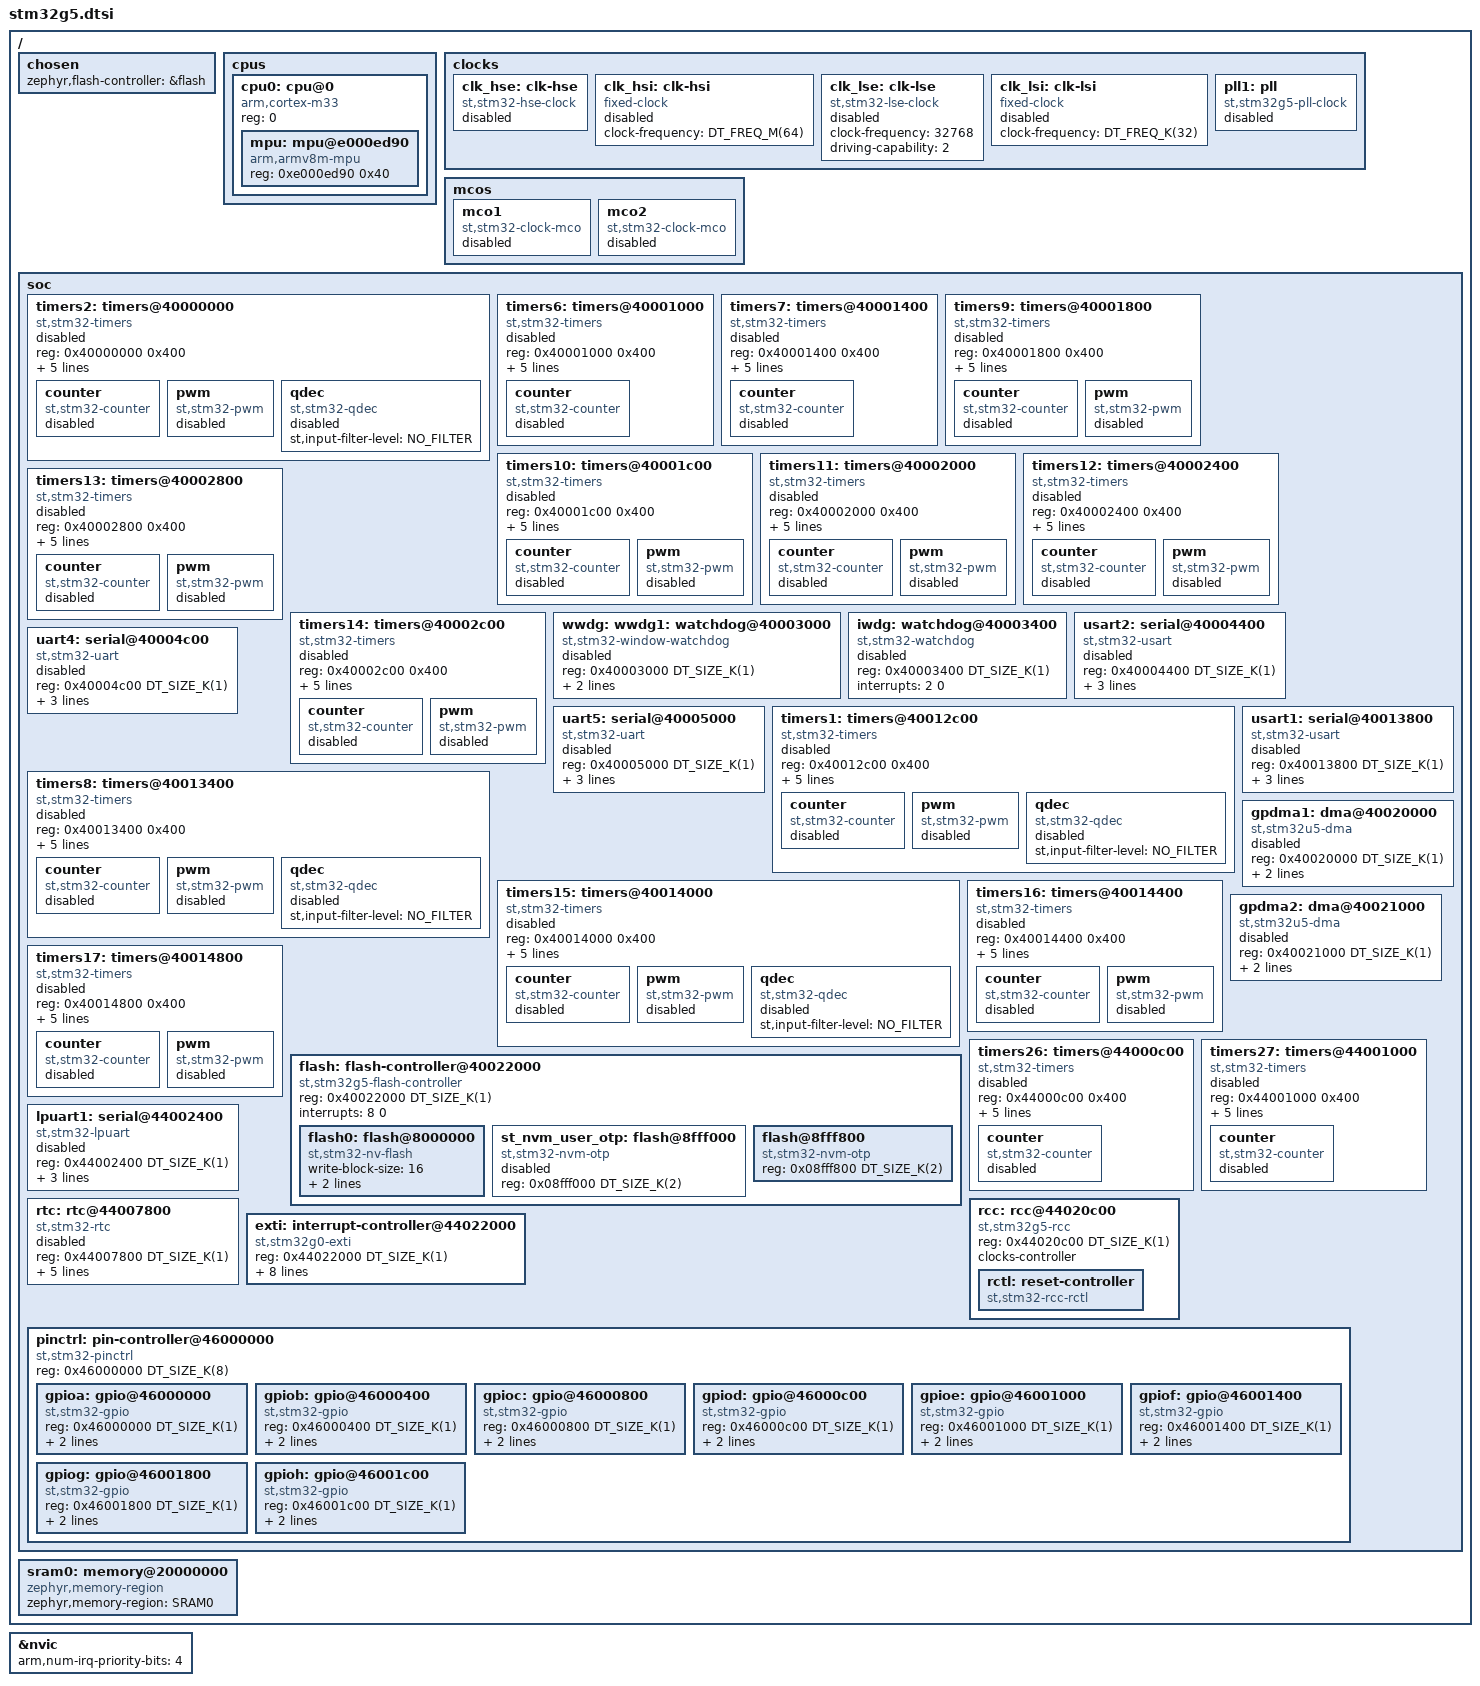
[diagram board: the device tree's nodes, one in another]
/*
 * Copyright (c) 2026 STMicroelectronics
 *
 * SPDX-License-Identifier: Apache-2.0
 */

#include <arm/armv8-m.dtsi>
#include <zephyr/dt-bindings/adc/adc.h>
#include <zephyr/dt-bindings/clock/stm32g5_clock.h>
#include <zephyr/dt-bindings/dma/stm32_dma.h>
#include <zephyr/dt-bindings/gpio/gpio.h>
#include <zephyr/dt-bindings/i2c/i2c.h>
#include <zephyr/dt-bindings/reset/stm32g5_reset.h>
#include <zephyr/dt-bindings/sensor/qdec_stm32.h>
#include <zephyr/dt-bindings/pwm/pwm.h>
#include <freq.h>

/ {
	chosen {
		zephyr,flash-controller = &flash;
	};

	cpus {
		#address-cells = <1>;
		#size-cells = <0>;

		cpu0: cpu@0 {
			compatible = "arm,cortex-m33";
			reg = <0>;
			device_type = "cpu";
			#address-cells = <1>;
			#size-cells = <1>;

			mpu: mpu@e000ed90 {
				compatible = "arm,armv8m-mpu";
				reg = <0xe000ed90 0x40>;
			};
		};
	};

	clocks {
		clk_hse: clk-hse {
			compatible = "st,stm32-hse-clock";
			#clock-cells = <0>;
			status = "disabled";
		};

		clk_hsi: clk-hsi {
			compatible = "fixed-clock";
			#clock-cells = <0>;
			clock-frequency = <DT_FREQ_M(64)>;
			status = "disabled";
		};

		clk_lse: clk-lse {
			compatible = "st,stm32-lse-clock";
			#clock-cells = <0>;
			clock-frequency = <32768>;
			driving-capability = <2>;
			status = "disabled";
		};

		clk_lsi: clk-lsi {
			compatible = "fixed-clock";
			#clock-cells = <0>;
			clock-frequency = <DT_FREQ_K(32)>;
			status = "disabled";
		};

		pll1: pll: pll {
			compatible = "st,stm32g5-pll-clock", "st,stm32u5-pll-clock";
			#clock-cells = <0>;
			status = "disabled";
		};
	};

	mcos {
		mco1: mco1 {
			compatible = "st,stm32-clock-mco";
			clock-names = "clksel";
			status = "disabled";
		};

		mco2: mco2 {
			compatible = "st,stm32-clock-mco";
			clock-names = "clksel";
			status = "disabled";
		};
	};

	soc {
		timers2: timers@40000000 {
			compatible = "st,stm32-timers";
			reg = <0x40000000 0x400>;
			clocks = <&rcc STM32_CLOCK(APB1, 0)>,
				 <&rcc STM32_SRC_HCLK4 NO_SEL>;
			resets = <&rctl STM32_RESET(APB1L, 0)>;
			interrupts = <52 0>;
			interrupt-names = "global";
			st,prescaler = <0>;
			status = "disabled";

			counter {
				compatible = "st,stm32-counter";
				status = "disabled";
			};

			pwm {
				compatible = "st,stm32-pwm";
				#pwm-cells = <3>;
				status = "disabled";
			};

			qdec {
				compatible = "st,stm32-qdec";
				st,input-filter-level = <NO_FILTER>;
				status = "disabled";
			};
		};

		timers6: timers@40001000 {
			compatible = "st,stm32-timers";
			reg = <0x40001000 0x400>;
			clocks = <&rcc STM32_CLOCK(APB1, 4)>,
				 <&rcc STM32_SRC_HCLK4 NO_SEL>;
			resets = <&rctl STM32_RESET(APB1L, 4)>;
			interrupts = <56 0>;
			interrupt-names = "global";
			st,prescaler = <0>;
			status = "disabled";

			counter {
				compatible = "st,stm32-counter";
				status = "disabled";
			};
		};

		timers7: timers@40001400 {
			compatible = "st,stm32-timers";
			reg = <0x40001400 0x400>;
			clocks = <&rcc STM32_CLOCK(APB1, 5)>,
				 <&rcc STM32_SRC_HCLK4 NO_SEL>;
			resets = <&rctl STM32_RESET(APB1L, 5)>;
			interrupts = <57 0>;
			interrupt-names = "global";
			st,prescaler = <0>;
			status = "disabled";

			counter {
				compatible = "st,stm32-counter";
				status = "disabled";
			};
		};

		timers9: timers@40001800 {
			compatible = "st,stm32-timers";
			reg = <0x40001800 0x400>;
			clocks = <&rcc STM32_CLOCK(APB1, 6)>,
				 <&rcc STM32_SRC_HCLK4 NO_SEL>;
			resets = <&rctl STM32_RESET(APB1L, 6)>;
			interrupts = <86 0>;
			interrupt-names = "global";
			st,prescaler = <0>;
			status = "disabled";

			counter {
				compatible = "st,stm32-counter";
				status = "disabled";
			};

			pwm {
				compatible = "st,stm32-pwm";
				#pwm-cells = <3>;
				status = "disabled";
			};
		};

		timers10: timers@40001c00 {
			compatible = "st,stm32-timers";
			reg = <0x40001c00 0x400>;
			clocks = <&rcc STM32_CLOCK(APB1, 7)>,
				 <&rcc STM32_SRC_HCLK4 NO_SEL>;
			resets = <&rctl STM32_RESET(APB1L, 7)>;
			interrupts = <122 0>;
			interrupt-names = "global";
			st,prescaler = <0>;
			status = "disabled";

			counter {
				compatible = "st,stm32-counter";
				status = "disabled";
			};

			pwm {
				compatible = "st,stm32-pwm";
				#pwm-cells = <3>;
				status = "disabled";
			};
		};

		timers11: timers@40002000 {
			compatible = "st,stm32-timers";
			reg = <0x40002000 0x400>;
			clocks = <&rcc STM32_CLOCK(APB1, 8)>,
				 <&rcc STM32_SRC_HCLK4 NO_SEL>;
			resets = <&rctl STM32_RESET(APB1L, 8)>;
			interrupts = <187 0>;
			interrupt-names = "global";
			st,prescaler = <0>;
			status = "disabled";

			counter {
				compatible = "st,stm32-counter";
				status = "disabled";
			};

			pwm {
				compatible = "st,stm32-pwm";
				#pwm-cells = <3>;
				status = "disabled";
			};
		};

		timers12: timers@40002400 {
			compatible = "st,stm32-timers";
			reg = <0x40002400 0x400>;
			clocks = <&rcc STM32_CLOCK(APB1, 9)>,
				 <&rcc STM32_SRC_HCLK4 NO_SEL>;
			resets = <&rctl STM32_RESET(APB1L, 9)>;
			interrupts = <123 0>;
			interrupt-names = "global";
			st,prescaler = <0>;
			status = "disabled";

			counter {
				compatible = "st,stm32-counter";
				status = "disabled";
			};

			pwm {
				compatible = "st,stm32-pwm";
				#pwm-cells = <3>;
				status = "disabled";
			};
		};

		timers13: timers@40002800 {
			compatible = "st,stm32-timers";
			reg = <0x40002800 0x400>;
			clocks = <&rcc STM32_CLOCK(APB1, 10)>,
				 <&rcc STM32_SRC_HCLK4 NO_SEL>;
			resets = <&rctl STM32_RESET(APB1L, 10)>;
			interrupts = <124 0>;
			interrupt-names = "global";
			st,prescaler = <0>;
			status = "disabled";

			counter {
				compatible = "st,stm32-counter";
				status = "disabled";
			};

			pwm {
				compatible = "st,stm32-pwm";
				#pwm-cells = <3>;
				status = "disabled";
			};
		};

		timers14: timers@40002c00 {
			compatible = "st,stm32-timers";
			reg = <0x40002c00 0x400>;
			clocks = <&rcc STM32_CLOCK(APB1, 11)>,
				 <&rcc STM32_SRC_HCLK4 NO_SEL>;
			resets = <&rctl STM32_RESET(APB1L, 11)>;
			interrupts = <125 0>;
			interrupt-names = "global";
			st,prescaler = <0>;
			status = "disabled";

			counter {
				compatible = "st,stm32-counter";
				status = "disabled";
			};

			pwm {
				compatible = "st,stm32-pwm";
				#pwm-cells = <3>;
				status = "disabled";
			};
		};

		wwdg: wwdg1: watchdog@40003000 {
			compatible = "st,stm32-window-watchdog";
			reg = <0x40003000 DT_SIZE_K(1)>;
			clocks = <&rcc STM32_CLOCK(APB1, 12)>;
			interrupts = <0 0>;
			status = "disabled";
		};

		iwdg: watchdog@40003400 {
			compatible = "st,stm32-watchdog";
			reg = <0x40003400 DT_SIZE_K(1)>;
			interrupts = <2 0>;
			status = "disabled";
		};

		usart2: serial@40004400 {
			compatible = "st,stm32-usart", "st,stm32-uart";
			reg = <0x40004400 DT_SIZE_K(1)>;
			clocks = <&rcc STM32_CLOCK(APB1, 17)>;
			resets = <&rctl STM32_RESET(APB1L, 17)>;
			interrupts = <66 0>;
			interrupt-names = "global";
			status = "disabled";
		};

		uart4: serial@40004c00 {
			compatible = "st,stm32-uart";
			reg = <0x40004c00 DT_SIZE_K(1)>;
			clocks = <&rcc STM32_CLOCK(APB1, 19)>;
			resets = <&rctl STM32_RESET(APB1L, 19)>;
			interrupts = <68 0>;
			interrupt-names = "global";
			status = "disabled";
		};

		uart5: serial@40005000 {
			compatible = "st,stm32-uart";
			reg = <0x40005000 DT_SIZE_K(1)>;
			clocks = <&rcc STM32_CLOCK(APB1, 20)>;
			resets = <&rctl STM32_RESET(APB1L, 20)>;
			interrupts = <69 0>;
			interrupt-names = "global";
			status = "disabled";
		};

		timers1: timers@40012c00 {
			compatible = "st,stm32-timers";
			reg = <0x40012c00 0x400>;
			clocks = <&rcc STM32_CLOCK(APB2, 11)>,
				 <&rcc STM32_SRC_HCLK4 NO_SEL>;
			resets = <&rctl STM32_RESET(APB2, 11)>;
			interrupts = <48 0>, <49 0>, <50 0>, <51 0>;
			interrupt-names = "brk", "up", "trgcom", "cc";
			st,prescaler = <0>;
			status = "disabled";

			counter {
				compatible = "st,stm32-counter";
				status = "disabled";
			};

			pwm {
				compatible = "st,stm32-pwm";
				#pwm-cells = <3>;
				status = "disabled";
			};

			qdec {
				compatible = "st,stm32-qdec";
				st,input-filter-level = <NO_FILTER>;
				status = "disabled";
			};
		};

		timers8: timers@40013400 {
			compatible = "st,stm32-timers";
			reg = <0x40013400 0x400>;
			clocks = <&rcc STM32_CLOCK(APB2, 13)>,
				 <&rcc STM32_SRC_HCLK4 NO_SEL>;
			resets = <&rctl STM32_RESET(APB2, 13)>;
			interrupts = <72 0>, <73 0>, <74 0>, <75 0>;
			interrupt-names = "brk", "up", "trgcom", "cc";
			st,prescaler = <0>;
			status = "disabled";

			counter {
				compatible = "st,stm32-counter";
				status = "disabled";
			};

			pwm {
				compatible = "st,stm32-pwm";
				#pwm-cells = <3>;
				status = "disabled";
			};

			qdec {
				compatible = "st,stm32-qdec";
				st,input-filter-level = <NO_FILTER>;
				status = "disabled";
			};
		};

		usart1: serial@40013800 {
			compatible = "st,stm32-usart", "st,stm32-uart";
			reg = <0x40013800 DT_SIZE_K(1)>;
			clocks = <&rcc STM32_CLOCK(APB2, 14)>;
			resets = <&rctl STM32_RESET(APB2, 14)>;
			interrupts = <65 0>;
			interrupt-names = "global";
			status = "disabled";
		};

		timers15: timers@40014000 {
			compatible = "st,stm32-timers";
			reg = <0x40014000 0x400>;
			clocks = <&rcc STM32_CLOCK(APB2, 16)>,
				 <&rcc STM32_SRC_HCLK4 NO_SEL>;
			resets = <&rctl STM32_RESET(APB2, 16)>;
			interrupts = <78 0>;
			interrupt-names = "global";
			st,prescaler = <0>;
			status = "disabled";

			counter {
				compatible = "st,stm32-counter";
				status = "disabled";
			};

			pwm {
				compatible = "st,stm32-pwm";
				#pwm-cells = <3>;
				status = "disabled";
			};

			qdec {
				compatible = "st,stm32-qdec";
				st,input-filter-level = <NO_FILTER>;
				status = "disabled";
			};
		};

		timers16: timers@40014400 {
			compatible = "st,stm32-timers";
			reg = <0x40014400 0x400>;
			clocks = <&rcc STM32_CLOCK(APB2, 17)>,
				 <&rcc STM32_SRC_HCLK4 NO_SEL>;
			resets = <&rctl STM32_RESET(APB2, 17)>;
			interrupts = <79 0>;
			interrupt-names = "global";
			st,prescaler = <0>;
			status = "disabled";

			counter {
				compatible = "st,stm32-counter";
				status = "disabled";
			};

			pwm {
				compatible = "st,stm32-pwm";
				#pwm-cells = <3>;
				status = "disabled";
			};
		};

		timers17: timers@40014800 {
			compatible = "st,stm32-timers";
			reg = <0x40014800 0x400>;
			clocks = <&rcc STM32_CLOCK(APB2, 18)>,
				 <&rcc STM32_SRC_HCLK4 NO_SEL>;
			resets = <&rctl STM32_RESET(APB2, 18)>;
			interrupts = <80 0>;
			interrupt-names = "global";
			st,prescaler = <0>;
			status = "disabled";

			counter {
				compatible = "st,stm32-counter";
				status = "disabled";
			};

			pwm {
				compatible = "st,stm32-pwm";
				#pwm-cells = <3>;
				status = "disabled";
			};
		};

		gpdma1: dma@40020000 {
			compatible = "st,stm32u5-dma";
			reg = <0x40020000 DT_SIZE_K(1)>;
			#dma-cells = <3>;
			clocks = <&rcc STM32_CLOCK(AHB1, 0)>;
			dma-requests = <157>;
			status = "disabled";
		};

		gpdma2: dma@40021000 {
			compatible = "st,stm32u5-dma";
			reg = <0x40021000 DT_SIZE_K(1)>;
			#dma-cells = <3>;
			clocks = <&rcc STM32_CLOCK(AHB1, 1)>;
			dma-requests = <157>;
			status = "disabled";
		};

		flash: flash-controller@40022000 {
			compatible = "st,stm32g5-flash-controller";
			reg = <0x40022000 DT_SIZE_K(1)>;
			ranges;
			interrupts = <8 0>;
			interrupt-names = "global";

			#address-cells = <1>;
			#size-cells = <1>;

			flash0: flash@8000000 {
				compatible = "st,stm32-nv-flash", "soc-nv-flash";
				#address-cells = <1>;
				#size-cells = <1>;
				write-block-size = <16>;
				erase-block-size = <8192>;
				max-erase-time = <5>;
			};

			st_nvm_user_otp: flash@8fff000 {
				compatible = "st,stm32-nvm-otp";
				reg = <0x08fff000 DT_SIZE_K(2)>;
				status = "disabled";
			};

			/* "Read-only area" */
			flash@8fff800 {
				compatible = "st,stm32-nvm-otp";
				reg = <0x08fff800 DT_SIZE_K(2)>;
			};
		};

		timers26: timers@44000c00 {
			compatible = "st,stm32-timers";
			reg = <0x44000c00 0x400>;
			clocks = <&rcc STM32_CLOCK(APB3, 3)>,
				 <&rcc STM32_SRC_HCLK4 NO_SEL>;
			resets = <&rctl STM32_RESET(APB3, 3)>;
			interrupts = <188 0>;
			interrupt-names = "global";
			st,prescaler = <0>;
			status = "disabled";

			counter {
				compatible = "st,stm32-counter";
				status = "disabled";
			};
		};

		timers27: timers@44001000 {
			compatible = "st,stm32-timers";
			reg = <0x44001000 0x400>;
			clocks = <&rcc STM32_CLOCK(APB3, 4)>,
				 <&rcc STM32_SRC_HCLK4 NO_SEL>;
			resets = <&rctl STM32_RESET(APB3, 4)>;
			interrupts = <189 0>;
			interrupt-names = "global";
			st,prescaler = <0>;
			status = "disabled";

			counter {
				compatible = "st,stm32-counter";
				status = "disabled";
			};
		};

		lpuart1: serial@44002400 {
			compatible = "st,stm32-lpuart", "st,stm32-uart";
			reg = <0x44002400 DT_SIZE_K(1)>;
			clocks = <&rcc STM32_CLOCK(APB3, 6)>;
			resets = <&rctl STM32_RESET(APB3, 6)>;
			interrupts = <70 0>;
			interrupt-names = "global";
			status = "disabled";
		};

		rtc: rtc@44007800 {
			compatible = "st,stm32-rtc";
			reg = <0x44007800 DT_SIZE_K(1)>;
			interrupts = <18 0>;
			interrupt-names = "global";
			clocks = <&rcc STM32_CLOCK(APB3, 23)>;
			prescaler = <32768>;
			alarms-count = <2>;
			alrm-exti-line = <17>;
			status = "disabled";
		};

		rcc: rcc@44020c00 {
			compatible = "st,stm32g5-rcc";
			reg = <0x44020c00 DT_SIZE_K(1)>;
			clocks-controller;
			#clock-cells = <2>;

			rctl: reset-controller {
				compatible = "st,stm32-rcc-rctl";
				#reset-cells = <1>;
			};
		};

		exti: interrupt-controller@44022000 {
			compatible = "st,stm32g0-exti", "st,stm32-exti";
			reg = <0x44022000 DT_SIZE_K(1)>;
			interrupt-controller;
			#interrupt-cells = <1>;
			#address-cells = <1>;
			num-lines = <40>;
			interrupts = <19 0>, <20 0>, <21 0>, <22 0>,
				     <23 0>, <24 0>, <25 0>, <26 0>,
				     <27 0>, <28 0>, <29 0>, <30 0>,
				     <31 0>, <32 0>, <33 0>, <34 0>;
			interrupt-names = "line0", "line1", "line2", "line3",
					  "line4", "line5", "line6", "line7",
					  "line8", "line9", "line10", "line11",
					  "line12", "line13", "line14", "line15";
			line-ranges = <0 1>, <1 1>, <2 1>, <3 1>,
				      <4 1>, <5 1>, <6 1>, <7 1>,
				      <8 1>, <9 1>, <10 1>, <11 1>,
				      <12 1>, <13 1>, <14 1>, <15 1>;
		};

		pinctrl: pin-controller@46000000 {
			compatible = "st,stm32-pinctrl";
			reg = <0x46000000 DT_SIZE_K(8)>;
			#address-cells = <1>;
			#size-cells = <1>;

			gpioa: gpio@46000000 {
				compatible = "st,stm32-gpio";
				reg = <0x46000000 DT_SIZE_K(1)>;
				gpio-controller;
				#gpio-cells = <2>;
				clocks = <&rcc STM32_CLOCK(AHB4, 9)>;
			};

			gpiob: gpio@46000400 {
				compatible = "st,stm32-gpio";
				reg = <0x46000400 DT_SIZE_K(1)>;
				gpio-controller;
				#gpio-cells = <2>;
				clocks = <&rcc STM32_CLOCK(AHB4, 10)>;
			};

			gpioc: gpio@46000800 {
				compatible = "st,stm32-gpio";
				reg = <0x46000800 DT_SIZE_K(1)>;
				gpio-controller;
				#gpio-cells = <2>;
				clocks = <&rcc STM32_CLOCK(AHB4, 11)>;
			};

			gpiod: gpio@46000c00 {
				compatible = "st,stm32-gpio";
				reg = <0x46000c00 DT_SIZE_K(1)>;
				gpio-controller;
				#gpio-cells = <2>;
				clocks = <&rcc STM32_CLOCK(AHB4, 12)>;
			};

			gpioe: gpio@46001000 {
				compatible = "st,stm32-gpio";
				reg = <0x46001000 DT_SIZE_K(1)>;
				gpio-controller;
				#gpio-cells = <2>;
				clocks = <&rcc STM32_CLOCK(AHB4, 13)>;
			};

			gpiof: gpio@46001400 {
				compatible = "st,stm32-gpio";
				reg = <0x46001400 DT_SIZE_K(1)>;
				gpio-controller;
				#gpio-cells = <2>;
				clocks = <&rcc STM32_CLOCK(AHB4, 14)>;
			};

			gpiog: gpio@46001800 {
				compatible = "st,stm32-gpio";
				reg = <0x46001800 DT_SIZE_K(1)>;
				gpio-controller;
				#gpio-cells = <2>;
				clocks = <&rcc STM32_CLOCK(AHB4, 15)>;
			};

			gpioh: gpio@46001c00 {
				compatible = "st,stm32-gpio";
				reg = <0x46001c00 DT_SIZE_K(1)>;
				gpio-controller;
				#gpio-cells = <2>;
				clocks = <&rcc STM32_CLOCK(AHB4, 16)>;
			};
		};
	};

	sram0: memory@20000000 {
		compatible = "zephyr,memory-region", "mmio-sram";
		zephyr,memory-region = "SRAM0";
	};
};

&nvic {
	arm,num-irq-priority-bits = <4>;
};
